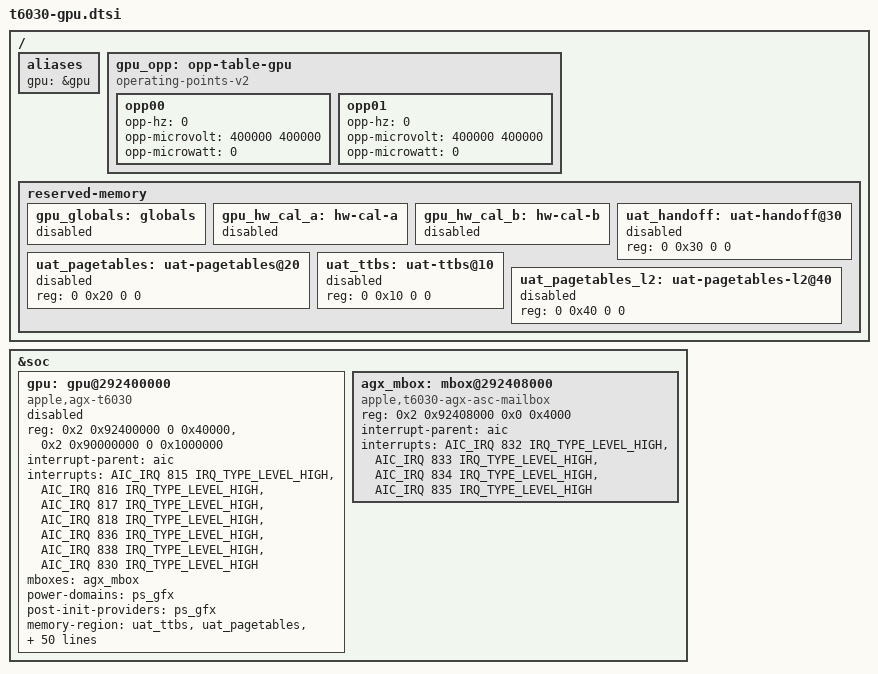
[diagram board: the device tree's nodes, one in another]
// SPDX-License-Identifier: GPL-2.0+ OR MIT
/*
 * Apple T6030 (M3 Pro / G15S) GPU. The boot loader fills in this machine's
 * values and the firmware memory, then enables the GPU.
 */

/ {
	aliases {
		gpu = &gpu;	/* the boot loader finds the GPU through this alias */
	};

	gpu_opp: opp-table-gpu {
		compatible = "operating-points-v2";

		/* Placeholder; the boot loader writes one OPP per pstate, per MGPU. */
		opp00 {
			opp-hz = /bits/ 64 <0>;
			opp-microvolt = <400000 400000>;
			opp-microwatt = <0>;
		};
		opp01 {
			opp-hz = /bits/ 64 <0>;
			opp-microvolt = <400000 400000>;
			opp-microwatt = <0>;
		};
	};

	reserved-memory {
		gpu_globals: globals {
			status = "disabled";
		};

		gpu_hw_cal_a: hw-cal-a {
			status = "disabled";
		};

		gpu_hw_cal_b: hw-cal-b {
			status = "disabled";
		};

		/* Filled and enabled by the boot loader; disabled while empty. */
		uat_handoff: uat-handoff@30 {
			reg = <0 0x30 0 0>;
			status = "disabled";
		};

		uat_pagetables: uat-pagetables@20 {
			reg = <0 0x20 0 0>;
			status = "disabled";
		};

		uat_ttbs: uat-ttbs@10 {
			reg = <0 0x10 0 0>;
			status = "disabled";
		};

		/* G15 TTBR1 level-2 table, in the linear map with uat-pagetables. */
		uat_pagetables_l2: uat-pagetables-l2@40 {
			reg = <0 0x40 0 0>;
			status = "disabled";
		};
	};
};

&soc {
	/* No DART: drm/asahi owns the UAT, as on T602x. */
	gpu: gpu@292400000 {
		compatible = "apple,agx-t6030", "apple,agx-g15x", "apple,agx-g15s";
		reg = <0x2 0x92400000 0 0x40000>,
			<0x2 0x90000000 0 0x1000000>;
		reg-names = "asc", "sgx";
		interrupt-parent = <&aic>;
		/* Entry 5 (838) is invalid in the ADT mask; kept, as on T602x. */
		interrupts = <AIC_IRQ 815 IRQ_TYPE_LEVEL_HIGH>,
			<AIC_IRQ 816 IRQ_TYPE_LEVEL_HIGH>,
			<AIC_IRQ 817 IRQ_TYPE_LEVEL_HIGH>,
			<AIC_IRQ 818 IRQ_TYPE_LEVEL_HIGH>,
			<AIC_IRQ 836 IRQ_TYPE_LEVEL_HIGH>,
			<AIC_IRQ 838 IRQ_TYPE_LEVEL_HIGH>,
			<AIC_IRQ 830 IRQ_TYPE_LEVEL_HIGH>;
		mboxes = <&agx_mbox>;
		power-domains = <&ps_gfx>;
		/* Do not hold back ps_gfx sync_state() if the GPU never probes. */
		post-init-providers = <&ps_gfx>;
		memory-region = <&uat_ttbs>, <&uat_pagetables>, <&uat_handoff>,
				<&gpu_hw_cal_a>, <&gpu_hw_cal_b>, <&gpu_globals>;
		memory-region-names = "ttbs", "pagetables", "handoff",
				      "hw-cal-a", "hw-cal-b", "globals";

		apple,firmware-abi = <0 0 0>;
		apple,firmware-version = <0 0 0>;
		apple,firmware-compat = <0 0 0>;

		/* No apple,cs-opp, apple,afr-opp or CS/AFR leak coefficients: this GPU has no CS or AFR domain. */
		operating-points-v2 = <&gpu_opp>;

		apple,min-sram-microvolt = <810000>;
		apple,perf-base-pstate = <1>;

		/* Power-management coefficients. Floats are IEEE-754 bit patterns. */
		apple,avg-power-filter-tc-ms = <40>;
		apple,avg-power-ki-only = <45.0>;
		apple,avg-power-kp = <1.4>;
		apple,avg-power-min-duty-cycle = <40>;
		apple,avg-power-target-filter-tc = <1>;
		apple,fast-die0-integral-gain = <1552.0>;
		apple,fast-die0-proportional-gain = <37.0>;
		apple,idleoff-standby-timer = <1500>;
		apple,perf-boost-ce-step = <50>;
		apple,perf-boost-min-util = <90>;
		apple,perf-filter-drop-threshold = <0>;
		apple,perf-filter-time-constant = <5>;
		apple,perf-filter-time-constant2 = <200>;
		apple,perf-integral-gain = <1.755>;
		apple,perf-integral-gain2 = <1.755>;
		apple,perf-integral-min-clamp = <0>;
		apple,perf-proportional-gain = <5.85>;
		apple,perf-proportional-gain2 = <5.85>;
		apple,perf-tgt-utilization = <80>;
		apple,power-sample-period = <8>;
		apple,ppm-filter-time-constant-ms = <32>;
		apple,ppm-ki = <28.0>;
		apple,ppm-kp = <0.1>;
		apple,pwr-filter-time-constant = <313>;
		apple,pwr-integral-gain = <0.0202129>;
		apple,pwr-integral-min-clamp = <0>;
		apple,pwr-min-duty-cycle = <40>;
		apple,pwr-proportional-gain = <5.2831855>;
		apple,pwr-sample-period-aic-clks = <200000>;
		apple,se-engagement-criteria = <600>;
		apple,se-filter-time-constant = <9>;
		apple,se-filter-time-constant-1 = <3>;
		apple,se-inactive-threshold = <2500>;
		apple,se-ki = <-50.0>;
		apple,se-ki-1 = <-100.0>;
		apple,se-kp = <-5.0>;
		apple,se-kp-1 = <-10.0>;
		apple,se-reset-criteria = <50>;
		/* One per MGPU; the boot loader writes the fused core leakage. */
		apple,core-leak-coef = <1.0 1.0>;
		apple,sram-leak-coef = <0.0 0.0>;

		/* The boot loader sets "okay" last. */
		status = "disabled";
	};

	/* No asc-mailbox-v4 fallback: unbound without G15 support. */
	agx_mbox: mbox@292408000 {
		compatible = "apple,t6030-agx-asc-mailbox";
		reg = <0x2 0x92408000 0x0 0x4000>;
		interrupt-parent = <&aic>;
		interrupts = <AIC_IRQ 832 IRQ_TYPE_LEVEL_HIGH>,
			<AIC_IRQ 833 IRQ_TYPE_LEVEL_HIGH>,
			<AIC_IRQ 834 IRQ_TYPE_LEVEL_HIGH>,
			<AIC_IRQ 835 IRQ_TYPE_LEVEL_HIGH>;
		interrupt-names = "send-empty", "send-not-empty",
			"recv-empty", "recv-not-empty";
		#mbox-cells = <0>;
	};
};
